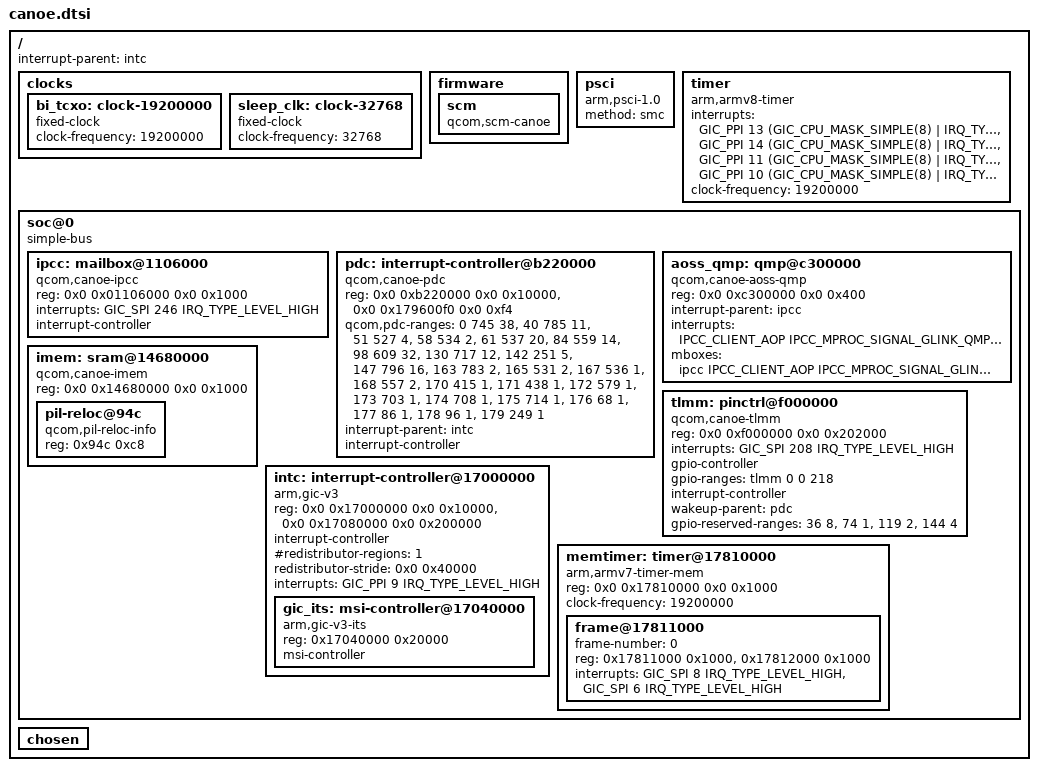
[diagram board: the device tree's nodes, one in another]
// SPDX-License-Identifier: BSD-3-Clause
/*
 * Copyright (c) 2026, Travis Mills <travismills82@gmail.com>
 */

#include <dt-bindings/interrupt-controller/arm-gic.h>
#include <dt-bindings/mailbox/qcom-ipcc.h>

/ {
	#address-cells = <2>;
	#size-cells = <2>;
	interrupt-parent = <&intc>;

	clocks {
		bi_tcxo: clock-19200000 {
			compatible = "fixed-clock";
			#clock-cells = <0>;
			clock-frequency = <19200000>;
		};

		sleep_clk: clock-32768 {
			compatible = "fixed-clock";
			#clock-cells = <0>;
			clock-frequency = <32768>;
		};
	};

	firmware {
		scm: scm {
			compatible = "qcom,scm-canoe", "qcom,scm";
		};
	};

	psci {
		compatible = "arm,psci-1.0";
		method = "smc";
	};

	timer {
		compatible = "arm,armv8-timer";
		interrupts = <GIC_PPI 13 (GIC_CPU_MASK_SIMPLE(8) | IRQ_TYPE_LEVEL_LOW)>,
			     <GIC_PPI 14 (GIC_CPU_MASK_SIMPLE(8) | IRQ_TYPE_LEVEL_LOW)>,
			     <GIC_PPI 11 (GIC_CPU_MASK_SIMPLE(8) | IRQ_TYPE_LEVEL_LOW)>,
			     <GIC_PPI 10 (GIC_CPU_MASK_SIMPLE(8) | IRQ_TYPE_LEVEL_LOW)>;
		clock-frequency = <19200000>;
	};

	soc@0 {
		compatible = "simple-bus";
		#address-cells = <2>;
		#size-cells = <2>;
		ranges = <0x0 0x0 0x0 0x0 0x10 0x0>;

		ipcc: mailbox@1106000 {
			compatible = "qcom,canoe-ipcc", "qcom,ipcc";
			reg = <0x0 0x01106000 0x0 0x1000>;

			interrupts = <GIC_SPI 246 IRQ_TYPE_LEVEL_HIGH>;
			interrupt-controller;
			#interrupt-cells = <3>;

			#mbox-cells = <2>;
		};

		pdc: interrupt-controller@b220000 {
			compatible = "qcom,canoe-pdc", "qcom,pdc";
			reg = <0x0 0xb220000 0x0 0x10000>,
			      <0x0 0x179600f0 0x0 0xf4>;
			qcom,pdc-ranges = <0 745 38>, <40 785 11>, <51 527 4>,
					  <58 534 2>, <61 537 20>, <84 559 14>,
					  <98 609 32>, <130 717 12>, <142 251 5>,
					  <147 796 16>, <163 783 2>, <165 531 2>,
					  <167 536 1>, <168 557 2>, <170 415 1>,
					  <171 438 1>, <172 579 1>, <173 703 1>,
					  <174 708 1>, <175 714 1>, <176 68 1>,
					  <177 86 1>, <178 96 1>, <179 249 1>;
			#interrupt-cells = <2>;
			interrupt-parent = <&intc>;
			interrupt-controller;
		};

		aoss_qmp: qmp@c300000 {
			compatible = "qcom,canoe-aoss-qmp", "qcom,aoss-qmp";
			reg = <0x0 0xc300000 0x0 0x400>;

			interrupt-parent = <&ipcc>;
			interrupts = <IPCC_CLIENT_AOP IPCC_MPROC_SIGNAL_GLINK_QMP
				      IRQ_TYPE_EDGE_RISING>;

			mboxes = <&ipcc IPCC_CLIENT_AOP IPCC_MPROC_SIGNAL_GLINK_QMP>;

			#clock-cells = <0>;
		};

		tlmm: pinctrl@f000000 {
			compatible = "qcom,canoe-tlmm";
			reg = <0x0 0xf000000 0x0 0x202000>;
			interrupts = <GIC_SPI 208 IRQ_TYPE_LEVEL_HIGH>;
			gpio-controller;
			#gpio-cells = <2>;
			gpio-ranges = <&tlmm 0 0 218>;
			interrupt-controller;
			#interrupt-cells = <2>;
			wakeup-parent = <&pdc>;
			gpio-reserved-ranges = <36 8>, <74 1>, <119 2>, <144 4>;
		};

		imem: sram@14680000 {
			compatible = "qcom,canoe-imem", "syscon", "simple-mfd";
			reg = <0x0 0x14680000 0x0 0x1000>;
			ranges = <0x0 0x0 0x14680000 0x1000>;
			#address-cells = <1>;
			#size-cells = <1>;

			pil-reloc@94c {
				compatible = "qcom,pil-reloc-info";
				reg = <0x94c 0xc8>;
			};
		};

		intc: interrupt-controller@17000000 {
			compatible = "arm,gic-v3";
			reg = <0x0 0x17000000 0x0 0x10000>,
			      <0x0 0x17080000 0x0 0x200000>;
			#address-cells = <1>;
			#size-cells = <1>;
			ranges;
			#interrupt-cells = <3>;
			interrupt-controller;
			#redistributor-regions = <1>;
			redistributor-stride = <0x0 0x40000>;
			interrupts = <GIC_PPI 9 IRQ_TYPE_LEVEL_HIGH>;

			gic_its: msi-controller@17040000 {
				compatible = "arm,gic-v3-its";
				reg = <0x17040000 0x20000>;
				msi-controller;
				#msi-cells = <1>;
			};
		};

		memtimer: timer@17810000 {
			compatible = "arm,armv7-timer-mem";
			reg = <0x0 0x17810000 0x0 0x1000>;
			#address-cells = <1>;
			#size-cells = <1>;
			ranges;
			clock-frequency = <19200000>;

			frame@17811000 {
				frame-number = <0>;
				reg = <0x17811000 0x1000>,
				      <0x17812000 0x1000>;
				interrupts = <GIC_SPI 8 IRQ_TYPE_LEVEL_HIGH>,
					     <GIC_SPI 6 IRQ_TYPE_LEVEL_HIGH>;
			};
		};
	};

	chosen {
	};
};
